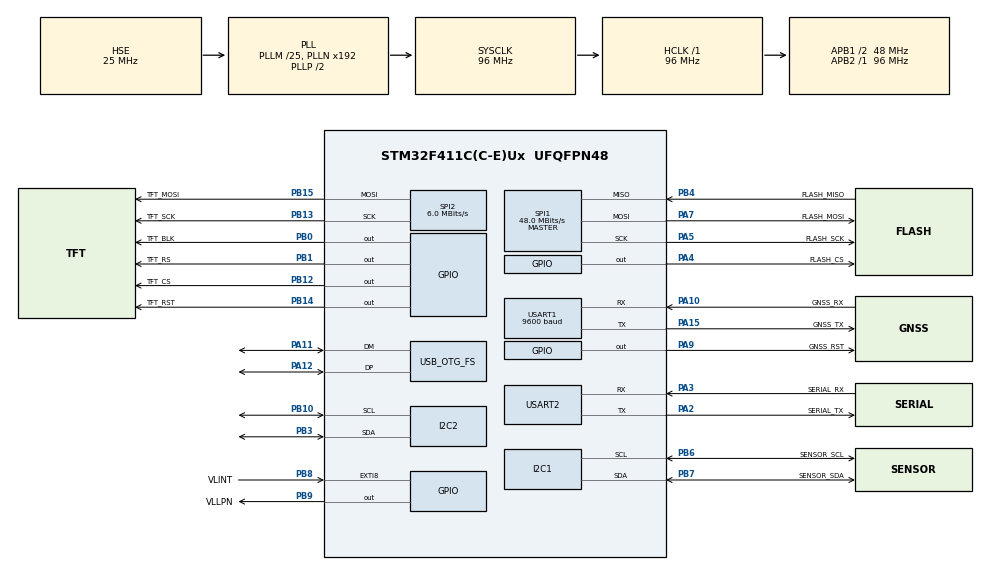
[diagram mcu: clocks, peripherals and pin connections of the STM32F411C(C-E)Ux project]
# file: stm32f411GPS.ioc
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Dma.I2C1_RX.5.Direction=DMA_PERIPH_TO_MEMORY
Dma.I2C1_RX.5.FIFOMode=DMA_FIFOMODE_DISABLE
Dma.I2C1_RX.5.Instance=DMA1_Stream0
Dma.I2C1_RX.5.MemDataAlignment=DMA_MDATAALIGN_BYTE
Dma.I2C1_RX.5.MemInc=DMA_MINC_ENABLE
Dma.I2C1_RX.5.Mode=DMA_NORMAL
Dma.I2C1_RX.5.PeriphDataAlignment=DMA_PDATAALIGN_BYTE
Dma.I2C1_RX.5.PeriphInc=DMA_PINC_DISABLE
Dma.I2C1_RX.5.Priority=DMA_PRIORITY_HIGH
Dma.I2C1_TX.8.Direction=DMA_MEMORY_TO_PERIPH
Dma.I2C1_TX.8.FIFOMode=DMA_FIFOMODE_DISABLE
Dma.I2C1_TX.8.Instance=DMA1_Stream1
Dma.I2C1_TX.8.MemDataAlignment=DMA_MDATAALIGN_BYTE
Dma.I2C1_TX.8.MemInc=DMA_MINC_ENABLE
Dma.I2C1_TX.8.Mode=DMA_NORMAL
Dma.I2C1_TX.8.PeriphDataAlignment=DMA_PDATAALIGN_BYTE
Dma.I2C1_TX.8.PeriphInc=DMA_PINC_DISABLE
Dma.I2C1_TX.8.Priority=DMA_PRIORITY_LOW
Dma.Request0=USART1_RX
Dma.Request1=USART1_TX
Dma.Request2=USART2_TX
Dma.Request3=USART2_RX
Dma.Request4=SPI1_TX
Dma.Request5=I2C1_RX
Dma.Request6=SPI1_RX
Dma.Request7=SPI2_TX
Dma.Request8=I2C1_TX
Dma.SPI1_RX.6.Direction=DMA_PERIPH_TO_MEMORY
Dma.SPI1_RX.6.FIFOMode=DMA_FIFOMODE_DISABLE
Dma.SPI1_RX.6.Instance=DMA2_Stream0
Dma.SPI1_RX.6.MemDataAlignment=DMA_MDATAALIGN_BYTE
Dma.SPI1_RX.6.MemInc=DMA_MINC_ENABLE
Dma.SPI1_RX.6.Mode=DMA_NORMAL
Dma.SPI1_RX.6.PeriphDataAlignment=DMA_PDATAALIGN_BYTE
Dma.SPI1_RX.6.PeriphInc=DMA_PINC_DISABLE
Dma.SPI1_RX.6.Priority=DMA_PRIORITY_LOW
Dma.SPI1_TX.4.Direction=DMA_MEMORY_TO_PERIPH
Dma.SPI1_TX.4.FIFOMode=DMA_FIFOMODE_DISABLE
Dma.SPI1_TX.4.Instance=DMA2_Stream3
Dma.SPI1_TX.4.MemDataAlignment=DMA_MDATAALIGN_BYTE
Dma.SPI1_TX.4.MemInc=DMA_MINC_ENABLE
Dma.SPI1_TX.4.Mode=DMA_NORMAL
Dma.SPI1_TX.4.PeriphDataAlignment=DMA_PDATAALIGN_BYTE
Dma.SPI1_TX.4.PeriphInc=DMA_PINC_DISABLE
Dma.SPI1_TX.4.Priority=DMA_PRIORITY_LOW
Dma.SPI2_TX.7.Direction=DMA_MEMORY_TO_PERIPH
Dma.SPI2_TX.7.FIFOMode=DMA_FIFOMODE_DISABLE
Dma.SPI2_TX.7.Instance=DMA1_Stream4
Dma.SPI2_TX.7.MemDataAlignment=DMA_MDATAALIGN_BYTE
Dma.SPI2_TX.7.MemInc=DMA_MINC_ENABLE
Dma.SPI2_TX.7.Mode=DMA_NORMAL
Dma.SPI2_TX.7.PeriphDataAlignment=DMA_PDATAALIGN_BYTE
Dma.SPI2_TX.7.PeriphInc=DMA_PINC_DISABLE
Dma.SPI2_TX.7.Priority=DMA_PRIORITY_LOW
Dma.USART1_RX.0.Direction=DMA_PERIPH_TO_MEMORY
Dma.USART1_RX.0.FIFOMode=DMA_FIFOMODE_DISABLE
Dma.USART1_RX.0.Instance=DMA2_Stream2
Dma.USART1_RX.0.MemDataAlignment=DMA_MDATAALIGN_BYTE
Dma.USART1_RX.0.MemInc=DMA_MINC_ENABLE
Dma.USART1_RX.0.Mode=DMA_NORMAL
Dma.USART1_RX.0.PeriphDataAlignment=DMA_PDATAALIGN_BYTE
Dma.USART1_RX.0.PeriphInc=DMA_PINC_DISABLE
Dma.USART1_RX.0.Priority=DMA_PRIORITY_LOW
Dma.USART1_TX.1.Direction=DMA_MEMORY_TO_PERIPH
Dma.USART1_TX.1.FIFOMode=DMA_FIFOMODE_DISABLE
Dma.USART1_TX.1.Instance=DMA2_Stream7
Dma.USART1_TX.1.MemDataAlignment=DMA_MDATAALIGN_BYTE
Dma.USART1_TX.1.MemInc=DMA_MINC_ENABLE
Dma.USART1_TX.1.Mode=DMA_NORMAL
Dma.USART1_TX.1.PeriphDataAlignment=DMA_PDATAALIGN_BYTE
Dma.USART1_TX.1.PeriphInc=DMA_PINC_DISABLE
Dma.USART1_TX.1.Priority=DMA_PRIORITY_LOW
Dma.USART2_RX.3.Direction=DMA_PERIPH_TO_MEMORY
Dma.USART2_RX.3.FIFOMode=DMA_FIFOMODE_DISABLE
Dma.USART2_RX.3.Instance=DMA1_Stream5
Dma.USART2_RX.3.MemDataAlignment=DMA_MDATAALIGN_BYTE
Dma.USART2_RX.3.MemInc=DMA_MINC_ENABLE
Dma.USART2_RX.3.Mode=DMA_NORMAL
Dma.USART2_RX.3.PeriphDataAlignment=DMA_PDATAALIGN_BYTE
Dma.USART2_RX.3.PeriphInc=DMA_PINC_DISABLE
Dma.USART2_RX.3.Priority=DMA_PRIORITY_LOW
Dma.USART2_TX.2.Direction=DMA_MEMORY_TO_PERIPH
Dma.USART2_TX.2.FIFOMode=DMA_FIFOMODE_DISABLE
Dma.USART2_TX.2.Instance=DMA1_Stream6
Dma.USART2_TX.2.MemDataAlignment=DMA_MDATAALIGN_BYTE
Dma.USART2_TX.2.MemInc=DMA_MINC_ENABLE
Dma.USART2_TX.2.Mode=DMA_NORMAL
Dma.USART2_TX.2.PeriphDataAlignment=DMA_PDATAALIGN_BYTE
Dma.USART2_TX.2.PeriphInc=DMA_PINC_DISABLE
Dma.USART2_TX.2.Priority=DMA_PRIORITY_LOW
FREERTOS.Tasks01=defaultTaskName,-3,128,defaultTask,Default,NULL,Dynamic,NULL,NULL
FREERTOS.configUSE_NEWLIB_REENTRANT=1
I2C1.I2C_Mode=I2C_Fast
Mcu.Family=STM32F4
Mcu.Name=STM32F411C(C-E)Ux
Mcu.Package=UFQFPN48
NVIC.DMA1_Stream0_IRQn=true\:12\:0\:true\:false\:true\:true\:false\:true\:true
NVIC.DMA1_Stream1_IRQn=true\:5\:0\:false\:false\:true\:true\:false\:true\:true
NVIC.DMA1_Stream4_IRQn=true\:5\:0\:false\:false\:true\:true\:false\:true\:true
NVIC.DMA1_Stream5_IRQn=true\:12\:0\:true\:false\:true\:true\:false\:true\:true
NVIC.DMA1_Stream6_IRQn=true\:12\:0\:true\:false\:true\:true\:false\:true\:true
NVIC.DMA2_Stream0_IRQn=true\:5\:0\:false\:false\:true\:true\:false\:true\:true
NVIC.DMA2_Stream2_IRQn=true\:12\:0\:true\:false\:true\:true\:false\:true\:true
NVIC.DMA2_Stream3_IRQn=true\:12\:0\:true\:false\:true\:true\:false\:true\:true
NVIC.DMA2_Stream7_IRQn=true\:12\:0\:true\:false\:true\:true\:false\:true\:true
NVIC.I2C1_ER_IRQn=true\:5\:0\:false\:false\:true\:true\:true\:true\:true
NVIC.I2C1_EV_IRQn=true\:5\:0\:false\:false\:true\:true\:true\:true\:true
NVIC.OTG_FS_IRQn=true\:5\:0\:false\:false\:true\:true\:false\:true\:true
NVIC.PriorityGroup=NVIC_PRIORITYGROUP_4
NVIC.SPI1_IRQn=true\:5\:0\:false\:false\:true\:true\:true\:true\:true
NVIC.SPI2_IRQn=true\:5\:0\:false\:false\:true\:true\:true\:true\:true
NVIC.TIM2_IRQn=true\:15\:0\:false\:false\:true\:false\:false\:true\:true
NVIC.TimeBase=TIM2_IRQn
NVIC.TimeBaseIP=TIM2
NVIC.USART1_IRQn=true\:12\:0\:true\:false\:true\:true\:true\:true\:true
NVIC.USART2_IRQn=true\:12\:0\:true\:false\:true\:true\:true\:true\:true
PA10.GPIO_Label=GNSS_RX
PA10.GPIO_PuPd=GPIO_PULLUP
PA10.Mode=Asynchronous
PA10.Signal=USART1_RX
PA11.Mode=Device_Only
PA11.Signal=USB_OTG_FS_DM
PA12.Mode=Device_Only
PA12.Signal=USB_OTG_FS_DP
PA13.Mode=Serial_Wire
PA13.Signal=SYS_JTMS-SWDIO
PA14.Mode=Serial_Wire
PA14.Signal=SYS_JTCK-SWCLK
PA15.GPIO_Label=GNSS_TX
PA15.GPIO_PuPd=GPIO_PULLUP
PA15.Mode=Asynchronous
PA15.Signal=USART1_TX
PA2.GPIO_Label=SERIAL_TX
PA2.Mode=Asynchronous
PA2.Signal=USART2_TX
PA3.GPIO_Label=SERIAL_RX
PA3.Mode=Asynchronous
PA3.Signal=USART2_RX
PA4.GPIO_Label=FLASH_CS
PA4.GPIO_PuPd=GPIO_PULLUP
PA4.Signal=GPIO_Output
PA5.GPIO_Label=FLASH_SCK
PA5.Mode=Full_Duplex_Master
PA5.Signal=SPI1_SCK
PA7.GPIO_Label=FLASH_MOSI
PA7.Mode=Full_Duplex_Master
PA7.Signal=SPI1_MOSI
PA9.GPIO_Label=GNSS_RST
PA9.GPIO_PuPd=GPIO_PULLUP
PA9.Signal=GPIO_Output
PB0.GPIO_Label=TFT_BLK
PB0.GPIO_PuPd=GPIO_PULLUP
PB0.Signal=GPIO_Output
PB1.GPIO_Label=TFT_RS
PB1.GPIO_PuPd=GPIO_PULLUP
PB1.Signal=GPIO_Output
PB10.Mode=I2C
PB10.Signal=I2C2_SCL
PB12.GPIO_Label=TFT_CS
PB12.GPIO_PuPd=GPIO_PULLUP
PB12.Signal=GPIO_Output
PB13.GPIO_Label=TFT_SCK
PB13.Mode=TX_Only_Simplex_Unidirect_Master
PB13.Signal=SPI2_SCK
PB14.GPIO_Label=TFT_RST
PB14.GPIO_PuPd=GPIO_PULLUP
PB14.Signal=GPIO_Output
PB15.GPIO_Label=TFT_MOSI
PB15.Mode=TX_Only_Simplex_Unidirect_Master
PB15.Signal=SPI2_MOSI
PB3.Mode=I2C
PB3.Signal=I2C2_SDA
PB4.GPIO_Label=FLASH_MISO
PB4.Mode=Full_Duplex_Master
PB4.Signal=SPI1_MISO
PB6.GPIO_Label=SENSOR_SCL
PB6.Mode=I2C
PB6.Signal=I2C1_SCL
PB7.GPIO_Label=SENSOR_SDA
PB7.Mode=I2C
PB7.Signal=I2C1_SDA
PB8.GPIO_Label=VLINT
PB8.Signal=GPXTI8
PB9.GPIO_Label=VLLPN
PB9.Signal=GPIO_Output
PC14-OSC32_IN.Mode=LSE-External-Oscillator
PC14-OSC32_IN.Signal=RCC_OSC32_IN
PC15-OSC32_OUT.Mode=LSE-External-Oscillator
PC15-OSC32_OUT.Signal=RCC_OSC32_OUT
PH0\ -\ OSC_IN.Mode=HSE-External-Oscillator
PH0\ -\ OSC_IN.Signal=RCC_OSC_IN
PH1\ -\ OSC_OUT.Mode=HSE-External-Oscillator
PH1\ -\ OSC_OUT.Signal=RCC_OSC_OUT
ProjectManager.HeapSize=0x200
ProjectManager.StackSize=0x400
ProjectManager.TargetToolchain=STM32CubeIDE
RCC.48MHZClocksFreq_Value=48000000
RCC.AHBFreq_Value=96000000
RCC.APB1CLKDivider=RCC_HCLK_DIV2
RCC.APB1Freq_Value=48000000
RCC.APB1TimFreq_Value=96000000
RCC.APB2Freq_Value=96000000
RCC.APB2TimFreq_Value=96000000
RCC.CortexFreq_Value=96000000
RCC.HCLKFreq_Value=96000000
RCC.HSE_VALUE=25000000
RCC.HSI_VALUE=16000000
RCC.PLLM=25
RCC.SYSCLKFreq_VALUE=96000000
RCC.SYSCLKSource=RCC_SYSCLKSOURCE_PLLCLK
RCC.VCOOutputFreq_Value=192000000
SPI1.BaudRatePrescaler=SPI_BAUDRATEPRESCALER_2
SPI1.CLKPolarity=SPI_POLARITY_LOW
SPI1.CalculateBaudRate=48.0 MBits/s
SPI1.Direction=SPI_DIRECTION_2LINES
SPI1.Mode=SPI_MODE_MASTER
SPI1.VirtualType=VM_MASTER
SPI2.BaudRatePrescaler=SPI_BAUDRATEPRESCALER_8
SPI2.CalculateBaudRate=6.0 MBits/s
SPI2.Direction=SPI_DIRECTION_2LINES
SPI2.Mode=SPI_MODE_MASTER
SPI2.VirtualType=VM_MASTER
TIM5.Prescaler=95
USART1.BaudRate=9600
USART1.VirtualMode=VM_ASYNC
USART2.VirtualMode=VM_ASYNC
USB_DEVICE.CLASS_NAME_FS=CDC
USB_DEVICE.VirtualMode=Cdc
USB_DEVICE.VirtualModeFS=Cdc_FS
USB_OTG_FS.VirtualMode=Device_Only
VP_FREERTOS_VS_CMSIS_V1.Mode=CMSIS_V1
VP_SYS_VS_tim2.Mode=TIM2
VP_TIM5_VS_ClockSourceINT.Mode=Internal
VP_USB_DEVICE_VS_USB_DEVICE_CDC_FS.Mode=CDC_FS
board=custom

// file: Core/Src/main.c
/* USER CODE BEGIN Header */
/**
  ******************************************************************************
  * @file           : main.c
  * @brief          : Main program body
  ******************************************************************************
  * @attention
  *
  * Copyright (c) 2023 STMicroelectronics.
  * All rights reserved.
  *
  * This software is licensed under terms that can be found in the LICENSE file
  * in the root directory of this software component.
  * If no LICENSE file comes with this software, it is provided AS-IS.
  *
  ******************************************************************************
  */
/* USER CODE END Header */
#include "main.h"
#include "cmsis_os.h"
#include "usb_device.h"

/* USER CODE BEGIN Includes */
#include "projectMain.h"
/* USER CODE END Includes */

osThreadId defaultTaskNameHandle;

void SystemClock_Config(void);
static void MX_GPIO_Init(void);
static void MX_DMA_Init(void);
static void MX_USART1_UART_Init(void);
static void MX_USART2_UART_Init(void);
static void MX_TIM5_Init(void);
static void MX_I2C1_Init(void);
static void MX_SPI1_Init(void);
static void MX_I2C2_Init(void);
static void MX_SPI2_Init(void);
void defaultTask(void const * argument);

/* USER CODE BEGIN PFP */
static void gnssTask(void *pvParameters);
static void lcdTask(void *pvParameters);
/* USER CODE END PFP */

int main(void)
{

  /* MCU Configuration--------------------------------------------------------*/

  /* Reset of all peripherals, Initializes the Flash interface and the Systick. */
  HAL_Init();

  /* Configure the system clock */
  SystemClock_Config();

  /* Initialize all configured peripherals */
  MX_GPIO_Init();
  MX_DMA_Init();
  MX_USART1_UART_Init();
  MX_USART2_UART_Init();
  MX_TIM5_Init();
  MX_I2C1_Init();
  MX_SPI1_Init();
  MX_I2C2_Init();
  MX_SPI2_Init();

  /* Create the thread(s) */
  /* definition and creation of defaultTaskName */
  osThreadDef(defaultTaskName, defaultTask, osPriorityIdle, 0, 128);
  defaultTaskNameHandle = osThreadCreate(osThread(defaultTaskName), NULL);

  /* USER CODE BEGIN RTOS_THREADS */
  /* add threads, ... */
  ProjectMain();
  /* USER CODE END RTOS_THREADS */

  /* Start scheduler */
  osKernelStart();
  /* We should never get here as control is now taken by the scheduler */
  /* Infinite loop */
  /* USER CODE BEGIN WHILE */
  while (1)
  {
    LL_mDelay(1000);
    /* USER CODE END WHILE */

  }
}

void SystemClock_Config(void)
{
  RCC_OscInitTypeDef RCC_OscInitStruct = {0};
  RCC_ClkInitTypeDef RCC_ClkInitStruct = {0};

  /** Configure the main internal regulator output voltage
  */
  __HAL_RCC_PWR_CLK_ENABLE();
  __HAL_PWR_VOLTAGESCALING_CONFIG(PWR_REGULATOR_VOLTAGE_SCALE1);

  /** Initializes the RCC Oscillators according to the specified parameters
  * in the RCC_OscInitTypeDef structure.
  */
  RCC_OscInitStruct.OscillatorType = RCC_OSCILLATORTYPE_HSE;
  RCC_OscInitStruct.HSEState = RCC_HSE_ON;
  RCC_OscInitStruct.PLL.PLLState = RCC_PLL_ON;
  RCC_OscInitStruct.PLL.PLLSource = RCC_PLLSOURCE_HSE;
  RCC_OscInitStruct.PLL.PLLM = 25;
  RCC_OscInitStruct.PLL.PLLN = 192;
  RCC_OscInitStruct.PLL.PLLP = RCC_PLLP_DIV2;
  RCC_OscInitStruct.PLL.PLLQ = 4;
  if (HAL_RCC_OscConfig(&RCC_OscInitStruct) != HAL_OK)
  {
    Error_Handler();
  }

  /** Initializes the CPU, AHB and APB buses clocks
  */
  RCC_ClkInitStruct.ClockType = RCC_CLOCKTYPE_HCLK|RCC_CLOCKTYPE_SYSCLK
                              |RCC_CLOCKTYPE_PCLK1|RCC_CLOCKTYPE_PCLK2;
  RCC_ClkInitStruct.SYSCLKSource = RCC_SYSCLKSOURCE_PLLCLK;
  RCC_ClkInitStruct.AHBCLKDivider = RCC_SYSCLK_DIV1;
  RCC_ClkInitStruct.APB1CLKDivider = RCC_HCLK_DIV2;
  RCC_ClkInitStruct.APB2CLKDivider = RCC_HCLK_DIV1;

  if (HAL_RCC_ClockConfig(&RCC_ClkInitStruct, FLASH_LATENCY_3) != HAL_OK)
  {
    Error_Handler();
  }
}

static void MX_I2C1_Init(void)
{

  LL_I2C_InitTypeDef I2C_InitStruct = {0};

  LL_GPIO_InitTypeDef GPIO_InitStruct = {0};

  LL_AHB1_GRP1_EnableClock(LL_AHB1_GRP1_PERIPH_GPIOB);
  /**I2C1 GPIO Configuration
  PB6   ------> I2C1_SCL
  PB7   ------> I2C1_SDA
  */
  GPIO_InitStruct.Pin = SENSOR_SCL_Pin|SENSOR_SDA_Pin;
  GPIO_InitStruct.Mode = LL_GPIO_MODE_ALTERNATE;
  GPIO_InitStruct.Speed = LL_GPIO_SPEED_FREQ_VERY_HIGH;
  GPIO_InitStruct.OutputType = LL_GPIO_OUTPUT_OPENDRAIN;
  GPIO_InitStruct.Pull = LL_GPIO_PULL_NO;
  GPIO_InitStruct.Alternate = LL_GPIO_AF_4;
  LL_GPIO_Init(GPIOB, &GPIO_InitStruct);

  /* Peripheral clock enable */
  LL_APB1_GRP1_EnableClock(LL_APB1_GRP1_PERIPH_I2C1);

  /* I2C1 DMA Init */

  /* I2C1_RX Init */
  LL_DMA_SetChannelSelection(DMA1, LL_DMA_STREAM_0, LL_DMA_CHANNEL_1);

  LL_DMA_SetDataTransferDirection(DMA1, LL_DMA_STREAM_0, LL_DMA_DIRECTION_PERIPH_TO_MEMORY);

  LL_DMA_SetStreamPriorityLevel(DMA1, LL_DMA_STREAM_0, LL_DMA_PRIORITY_HIGH);

  LL_DMA_SetMode(DMA1, LL_DMA_STREAM_0, LL_DMA_MODE_NORMAL);

  LL_DMA_SetPeriphIncMode(DMA1, LL_DMA_STREAM_0, LL_DMA_PERIPH_NOINCREMENT);

  LL_DMA_SetMemoryIncMode(DMA1, LL_DMA_STREAM_0, LL_DMA_MEMORY_INCREMENT);

  LL_DMA_SetPeriphSize(DMA1, LL_DMA_STREAM_0, LL_DMA_PDATAALIGN_BYTE);

  LL_DMA_SetMemorySize(DMA1, LL_DMA_STREAM_0, LL_DMA_MDATAALIGN_BYTE);

  LL_DMA_DisableFifoMode(DMA1, LL_DMA_STREAM_0);

  /* I2C1_TX Init */
  LL_DMA_SetChannelSelection(DMA1, LL_DMA_STREAM_1, LL_DMA_CHANNEL_0);

  LL_DMA_SetDataTransferDirection(DMA1, LL_DMA_STREAM_1, LL_DMA_DIRECTION_MEMORY_TO_PERIPH);

  LL_DMA_SetStreamPriorityLevel(DMA1, LL_DMA_STREAM_1, LL_DMA_PRIORITY_LOW);

  LL_DMA_SetMode(DMA1, LL_DMA_STREAM_1, LL_DMA_MODE_NORMAL);

  LL_DMA_SetPeriphIncMode(DMA1, LL_DMA_STREAM_1, LL_DMA_PERIPH_NOINCREMENT);

  LL_DMA_SetMemoryIncMode(DMA1, LL_DMA_STREAM_1, LL_DMA_MEMORY_INCREMENT);

  LL_DMA_SetPeriphSize(DMA1, LL_DMA_STREAM_1, LL_DMA_PDATAALIGN_BYTE);

  LL_DMA_SetMemorySize(DMA1, LL_DMA_STREAM_1, LL_DMA_MDATAALIGN_BYTE);

  LL_DMA_DisableFifoMode(DMA1, LL_DMA_STREAM_1);

  /* I2C1 interrupt Init */
  NVIC_SetPriority(I2C1_EV_IRQn, NVIC_EncodePriority(NVIC_GetPriorityGrouping(),5, 0));
  NVIC_EnableIRQ(I2C1_EV_IRQn);
  NVIC_SetPriority(I2C1_ER_IRQn, NVIC_EncodePriority(NVIC_GetPriorityGrouping(),5, 0));
  NVIC_EnableIRQ(I2C1_ER_IRQn);

  /** I2C Initialization
  */
  LL_I2C_DisableOwnAddress2(I2C1);
  LL_I2C_DisableGeneralCall(I2C1);
  LL_I2C_EnableClockStretching(I2C1);
  I2C_InitStruct.PeripheralMode = LL_I2C_MODE_I2C;
  I2C_InitStruct.ClockSpeed = 400000;
  I2C_InitStruct.DutyCycle = LL_I2C_DUTYCYCLE_2;
  I2C_InitStruct.OwnAddress1 = 0;
  I2C_InitStruct.TypeAcknowledge = LL_I2C_ACK;
  I2C_InitStruct.OwnAddrSize = LL_I2C_OWNADDRESS1_7BIT;
  LL_I2C_Init(I2C1, &I2C_InitStruct);
  LL_I2C_SetOwnAddress2(I2C1, 0);

}

static void MX_I2C2_Init(void)
{

  LL_I2C_InitTypeDef I2C_InitStruct = {0};

  LL_GPIO_InitTypeDef GPIO_InitStruct = {0};

  LL_AHB1_GRP1_EnableClock(LL_AHB1_GRP1_PERIPH_GPIOB);
  /**I2C2 GPIO Configuration
  PB10   ------> I2C2_SCL
  PB3   ------> I2C2_SDA
  */
  GPIO_InitStruct.Pin = LL_GPIO_PIN_10;
  GPIO_InitStruct.Mode = LL_GPIO_MODE_ALTERNATE;
  GPIO_InitStruct.Speed = LL_GPIO_SPEED_FREQ_VERY_HIGH;
  GPIO_InitStruct.OutputType = LL_GPIO_OUTPUT_OPENDRAIN;
  GPIO_InitStruct.Pull = LL_GPIO_PULL_NO;
  GPIO_InitStruct.Alternate = LL_GPIO_AF_4;
  LL_GPIO_Init(GPIOB, &GPIO_InitStruct);

  GPIO_InitStruct.Pin = LL_GPIO_PIN_3;
  GPIO_InitStruct.Mode = LL_GPIO_MODE_ALTERNATE;
  GPIO_InitStruct.Speed = LL_GPIO_SPEED_FREQ_VERY_HIGH;
  GPIO_InitStruct.OutputType = LL_GPIO_OUTPUT_OPENDRAIN;
  GPIO_InitStruct.Pull = LL_GPIO_PULL_NO;
  GPIO_InitStruct.Alternate = LL_GPIO_AF_9;
  LL_GPIO_Init(GPIOB, &GPIO_InitStruct);

  /* Peripheral clock enable */
  LL_APB1_GRP1_EnableClock(LL_APB1_GRP1_PERIPH_I2C2);

  /** I2C Initialization
  */
  LL_I2C_DisableOwnAddress2(I2C2);
  LL_I2C_DisableGeneralCall(I2C2);
  LL_I2C_EnableClockStretching(I2C2);
  I2C_InitStruct.PeripheralMode = LL_I2C_MODE_I2C;
  I2C_InitStruct.ClockSpeed = 100000;
  I2C_InitStruct.DutyCycle = LL_I2C_DUTYCYCLE_2;
  I2C_InitStruct.OwnAddress1 = 0;
  I2C_InitStruct.TypeAcknowledge = LL_I2C_ACK;
  I2C_InitStruct.OwnAddrSize = LL_I2C_OWNADDRESS1_7BIT;
  LL_I2C_Init(I2C2, &I2C_InitStruct);
  LL_I2C_SetOwnAddress2(I2C2, 0);

}

static void MX_SPI1_Init(void)
{

  LL_SPI_InitTypeDef SPI_InitStruct = {0};

  LL_GPIO_InitTypeDef GPIO_InitStruct = {0};

  /* Peripheral clock enable */
  LL_APB2_GRP1_EnableClock(LL_APB2_GRP1_PERIPH_SPI1);

  LL_AHB1_GRP1_EnableClock(LL_AHB1_GRP1_PERIPH_GPIOA);
  LL_AHB1_GRP1_EnableClock(LL_AHB1_GRP1_PERIPH_GPIOB);
  /**SPI1 GPIO Configuration
  PA5   ------> SPI1_SCK
  PA7   ------> SPI1_MOSI
  PB4   ------> SPI1_MISO
  */
  GPIO_InitStruct.Pin = FLASH_SCK_Pin|FLASH_MOSI_Pin;
  GPIO_InitStruct.Mode = LL_GPIO_MODE_ALTERNATE;
  GPIO_InitStruct.Speed = LL_GPIO_SPEED_FREQ_VERY_HIGH;
  GPIO_InitStruct.OutputType = LL_GPIO_OUTPUT_PUSHPULL;
  GPIO_InitStruct.Pull = LL_GPIO_PULL_NO;
  GPIO_InitStruct.Alternate = LL_GPIO_AF_5;
  LL_GPIO_Init(GPIOA, &GPIO_InitStruct);

  GPIO_InitStruct.Pin = FLASH_MISO_Pin;
  GPIO_InitStruct.Mode = LL_GPIO_MODE_ALTERNATE;
  GPIO_InitStruct.Speed = LL_GPIO_SPEED_FREQ_VERY_HIGH;
  GPIO_InitStruct.OutputType = LL_GPIO_OUTPUT_PUSHPULL;
  GPIO_InitStruct.Pull = LL_GPIO_PULL_NO;
  GPIO_InitStruct.Alternate = LL_GPIO_AF_5;
  LL_GPIO_Init(FLASH_MISO_GPIO_Port, &GPIO_InitStruct);

  /* SPI1 DMA Init */

  /* SPI1_TX Init */
  LL_DMA_SetChannelSelection(DMA2, LL_DMA_STREAM_3, LL_DMA_CHANNEL_3);

  LL_DMA_SetDataTransferDirection(DMA2, LL_DMA_STREAM_3, LL_DMA_DIRECTION_MEMORY_TO_PERIPH);

  LL_DMA_SetStreamPriorityLevel(DMA2, LL_DMA_STREAM_3, LL_DMA_PRIORITY_LOW);

  LL_DMA_SetMode(DMA2, LL_DMA_STREAM_3, LL_DMA_MODE_NORMAL);

  LL_DMA_SetPeriphIncMode(DMA2, LL_DMA_STREAM_3, LL_DMA_PERIPH_NOINCREMENT);

  LL_DMA_SetMemoryIncMode(DMA2, LL_DMA_STREAM_3, LL_DMA_MEMORY_INCREMENT);

  LL_DMA_SetPeriphSize(DMA2, LL_DMA_STREAM_3, LL_DMA_PDATAALIGN_BYTE);

  LL_DMA_SetMemorySize(DMA2, LL_DMA_STREAM_3, LL_DMA_MDATAALIGN_BYTE);

  LL_DMA_DisableFifoMode(DMA2, LL_DMA_STREAM_3);

  /* SPI1_RX Init */
  LL_DMA_SetChannelSelection(DMA2, LL_DMA_STREAM_0, LL_DMA_CHANNEL_3);

  LL_DMA_SetDataTransferDirection(DMA2, LL_DMA_STREAM_0, LL_DMA_DIRECTION_PERIPH_TO_MEMORY);

  LL_DMA_SetStreamPriorityLevel(DMA2, LL_DMA_STREAM_0, LL_DMA_PRIORITY_LOW);

  LL_DMA_SetMode(DMA2, LL_DMA_STREAM_0, LL_DMA_MODE_NORMAL);

  LL_DMA_SetPeriphIncMode(DMA2, LL_DMA_STREAM_0, LL_DMA_PERIPH_NOINCREMENT);

  LL_DMA_SetMemoryIncMode(DMA2, LL_DMA_STREAM_0, LL_DMA_MEMORY_INCREMENT);

  LL_DMA_SetPeriphSize(DMA2, LL_DMA_STREAM_0, LL_DMA_PDATAALIGN_BYTE);

  LL_DMA_SetMemorySize(DMA2, LL_DMA_STREAM_0, LL_DMA_MDATAALIGN_BYTE);

  LL_DMA_DisableFifoMode(DMA2, LL_DMA_STREAM_0);

  /* SPI1 interrupt Init */
  NVIC_SetPriority(SPI1_IRQn, NVIC_EncodePriority(NVIC_GetPriorityGrouping(),5, 0));
  NVIC_EnableIRQ(SPI1_IRQn);

  /* SPI1 parameter configuration*/
  SPI_InitStruct.TransferDirection = LL_SPI_FULL_DUPLEX;
  SPI_InitStruct.Mode = LL_SPI_MODE_MASTER;
  SPI_InitStruct.DataWidth = LL_SPI_DATAWIDTH_8BIT;
  SPI_InitStruct.ClockPolarity = LL_SPI_POLARITY_LOW;
  SPI_InitStruct.ClockPhase = LL_SPI_PHASE_1EDGE;
  SPI_InitStruct.NSS = LL_SPI_NSS_SOFT;
  SPI_InitStruct.BaudRate = LL_SPI_BAUDRATEPRESCALER_DIV2;
  SPI_InitStruct.BitOrder = LL_SPI_MSB_FIRST;
  SPI_InitStruct.CRCCalculation = LL_SPI_CRCCALCULATION_DISABLE;
  SPI_InitStruct.CRCPoly = 10;
  LL_SPI_Init(SPI1, &SPI_InitStruct);
  LL_SPI_SetStandard(SPI1, LL_SPI_PROTOCOL_MOTOROLA);

}

static void MX_SPI2_Init(void)
{

  LL_SPI_InitTypeDef SPI_InitStruct = {0};

  LL_GPIO_InitTypeDef GPIO_InitStruct = {0};

  /* Peripheral clock enable */
  LL_APB1_GRP1_EnableClock(LL_APB1_GRP1_PERIPH_SPI2);

  LL_AHB1_GRP1_EnableClock(LL_AHB1_GRP1_PERIPH_GPIOB);
  /**SPI2 GPIO Configuration
  PB13   ------> SPI2_SCK
  PB15   ------> SPI2_MOSI
  */
  GPIO_InitStruct.Pin = TFT_SCK_Pin|TFT_MOSI_Pin;
  GPIO_InitStruct.Mode = LL_GPIO_MODE_ALTERNATE;
  GPIO_InitStruct.Speed = LL_GPIO_SPEED_FREQ_VERY_HIGH;
  GPIO_InitStruct.OutputType = LL_GPIO_OUTPUT_PUSHPULL;
  GPIO_InitStruct.Pull = LL_GPIO_PULL_NO;
  GPIO_InitStruct.Alternate = LL_GPIO_AF_5;
  LL_GPIO_Init(GPIOB, &GPIO_InitStruct);

  /* SPI2 DMA Init */

  /* SPI2_TX Init */
  LL_DMA_SetChannelSelection(DMA1, LL_DMA_STREAM_4, LL_DMA_CHANNEL_0);

  LL_DMA_SetDataTransferDirection(DMA1, LL_DMA_STREAM_4, LL_DMA_DIRECTION_MEMORY_TO_PERIPH);

  LL_DMA_SetStreamPriorityLevel(DMA1, LL_DMA_STREAM_4, LL_DMA_PRIORITY_LOW);

  LL_DMA_SetMode(DMA1, LL_DMA_STREAM_4, LL_DMA_MODE_NORMAL);

  LL_DMA_SetPeriphIncMode(DMA1, LL_DMA_STREAM_4, LL_DMA_PERIPH_NOINCREMENT);

  LL_DMA_SetMemoryIncMode(DMA1, LL_DMA_STREAM_4, LL_DMA_MEMORY_INCREMENT);

  LL_DMA_SetPeriphSize(DMA1, LL_DMA_STREAM_4, LL_DMA_PDATAALIGN_BYTE);

  LL_DMA_SetMemorySize(DMA1, LL_DMA_STREAM_4, LL_DMA_MDATAALIGN_BYTE);

  LL_DMA_DisableFifoMode(DMA1, LL_DMA_STREAM_4);

  /* SPI2 interrupt Init */
  NVIC_SetPriority(SPI2_IRQn, NVIC_EncodePriority(NVIC_GetPriorityGrouping(),5, 0));
  NVIC_EnableIRQ(SPI2_IRQn);

  /* SPI2 parameter configuration*/
  SPI_InitStruct.TransferDirection = LL_SPI_FULL_DUPLEX;
  SPI_InitStruct.Mode = LL_SPI_MODE_MASTER;
  SPI_InitStruct.DataWidth = LL_SPI_DATAWIDTH_8BIT;
  SPI_InitStruct.ClockPolarity = LL_SPI_POLARITY_LOW;
  SPI_InitStruct.ClockPhase = LL_SPI_PHASE_1EDGE;
  SPI_InitStruct.NSS = LL_SPI_NSS_SOFT;
  SPI_InitStruct.BaudRate = LL_SPI_BAUDRATEPRESCALER_DIV8;
  SPI_InitStruct.BitOrder = LL_SPI_MSB_FIRST;
  SPI_InitStruct.CRCCalculation = LL_SPI_CRCCALCULATION_DISABLE;
  SPI_InitStruct.CRCPoly = 10;
  LL_SPI_Init(SPI2, &SPI_InitStruct);
  LL_SPI_SetStandard(SPI2, LL_SPI_PROTOCOL_MOTOROLA);

}

static void MX_TIM5_Init(void)
{

  LL_TIM_InitTypeDef TIM_InitStruct = {0};

  /* Peripheral clock enable */
  LL_APB1_GRP1_EnableClock(LL_APB1_GRP1_PERIPH_TIM5);

  TIM_InitStruct.Prescaler = 95;
  TIM_InitStruct.CounterMode = LL_TIM_COUNTERMODE_UP;
  TIM_InitStruct.Autoreload = 4294967295;
  TIM_InitStruct.ClockDivision = LL_TIM_CLOCKDIVISION_DIV1;
  LL_TIM_Init(TIM5, &TIM_InitStruct);
  LL_TIM_DisableARRPreload(TIM5);
  LL_TIM_SetClockSource(TIM5, LL_TIM_CLOCKSOURCE_INTERNAL);
  LL_TIM_SetTriggerOutput(TIM5, LL_TIM_TRGO_RESET);
  LL_TIM_DisableMasterSlaveMode(TIM5);

}

static void MX_USART1_UART_Init(void)
{

  LL_USART_InitTypeDef USART_InitStruct = {0};

  LL_GPIO_InitTypeDef GPIO_InitStruct = {0};

  /* Peripheral clock enable */
  LL_APB2_GRP1_EnableClock(LL_APB2_GRP1_PERIPH_USART1);

  LL_AHB1_GRP1_EnableClock(LL_AHB1_GRP1_PERIPH_GPIOA);
  /**USART1 GPIO Configuration
  PA10   ------> USART1_RX
  PA15   ------> USART1_TX
  */
  GPIO_InitStruct.Pin = GNSS_RX_Pin|GNSS_TX_Pin;
  GPIO_InitStruct.Mode = LL_GPIO_MODE_ALTERNATE;
  GPIO_InitStruct.Speed = LL_GPIO_SPEED_FREQ_VERY_HIGH;
  GPIO_InitStruct.OutputType = LL_GPIO_OUTPUT_PUSHPULL;
  GPIO_InitStruct.Pull = LL_GPIO_PULL_UP;
  GPIO_InitStruct.Alternate = LL_GPIO_AF_7;
  LL_GPIO_Init(GPIOA, &GPIO_InitStruct);

  /* USART1 DMA Init */

  /* USART1_RX Init */
  LL_DMA_SetChannelSelection(DMA2, LL_DMA_STREAM_2, LL_DMA_CHANNEL_4);

  LL_DMA_SetDataTransferDirection(DMA2, LL_DMA_STREAM_2, LL_DMA_DIRECTION_PERIPH_TO_MEMORY);

  LL_DMA_SetStreamPriorityLevel(DMA2, LL_DMA_STREAM_2, LL_DMA_PRIORITY_LOW);

  LL_DMA_SetMode(DMA2, LL_DMA_STREAM_2, LL_DMA_MODE_NORMAL);

  LL_DMA_SetPeriphIncMode(DMA2, LL_DMA_STREAM_2, LL_DMA_PERIPH_NOINCREMENT);

  LL_DMA_SetMemoryIncMode(DMA2, LL_DMA_STREAM_2, LL_DMA_MEMORY_INCREMENT);

  LL_DMA_SetPeriphSize(DMA2, LL_DMA_STREAM_2, LL_DMA_PDATAALIGN_BYTE);

  LL_DMA_SetMemorySize(DMA2, LL_DMA_STREAM_2, LL_DMA_MDATAALIGN_BYTE);

  LL_DMA_DisableFifoMode(DMA2, LL_DMA_STREAM_2);

  /* USART1_TX Init */
  LL_DMA_SetChannelSelection(DMA2, LL_DMA_STREAM_7, LL_DMA_CHANNEL_4);

  LL_DMA_SetDataTransferDirection(DMA2, LL_DMA_STREAM_7, LL_DMA_DIRECTION_MEMORY_TO_PERIPH);

  LL_DMA_SetStreamPriorityLevel(DMA2, LL_DMA_STREAM_7, LL_DMA_PRIORITY_LOW);

  LL_DMA_SetMode(DMA2, LL_DMA_STREAM_7, LL_DMA_MODE_NORMAL);

  LL_DMA_SetPeriphIncMode(DMA2, LL_DMA_STREAM_7, LL_DMA_PERIPH_NOINCREMENT);

  LL_DMA_SetMemoryIncMode(DMA2, LL_DMA_STREAM_7, LL_DMA_MEMORY_INCREMENT);

  LL_DMA_SetPeriphSize(DMA2, LL_DMA_STREAM_7, LL_DMA_PDATAALIGN_BYTE);

  LL_DMA_SetMemorySize(DMA2, LL_DMA_STREAM_7, LL_DMA_MDATAALIGN_BYTE);

  LL_DMA_DisableFifoMode(DMA2, LL_DMA_STREAM_7);

  /* USART1 interrupt Init */
  NVIC_SetPriority(USART1_IRQn, NVIC_EncodePriority(NVIC_GetPriorityGrouping(),12, 0));
  NVIC_EnableIRQ(USART1_IRQn);

  USART_InitStruct.BaudRate = 9600;
  USART_InitStruct.DataWidth = LL_USART_DATAWIDTH_8B;
  USART_InitStruct.StopBits = LL_USART_STOPBITS_1;
  USART_InitStruct.Parity = LL_USART_PARITY_NONE;
  USART_InitStruct.TransferDirection = LL_USART_DIRECTION_TX_RX;
  USART_InitStruct.HardwareFlowControl = LL_USART_HWCONTROL_NONE;
  USART_InitStruct.OverSampling = LL_USART_OVERSAMPLING_16;
  LL_USART_Init(USART1, &USART_InitStruct);
  LL_USART_ConfigAsyncMode(USART1);
  LL_USART_Enable(USART1);

}

static void MX_USART2_UART_Init(void)
{

  LL_USART_InitTypeDef USART_InitStruct = {0};

  LL_GPIO_InitTypeDef GPIO_InitStruct = {0};

  /* Peripheral clock enable */
  LL_APB1_GRP1_EnableClock(LL_APB1_GRP1_PERIPH_USART2);

  LL_AHB1_GRP1_EnableClock(LL_AHB1_GRP1_PERIPH_GPIOA);
  /**USART2 GPIO Configuration
  PA2   ------> USART2_TX
  PA3   ------> USART2_RX
  */
  GPIO_InitStruct.Pin = SERIAL_TX_Pin|SERIAL_RX_Pin;
  GPIO_InitStruct.Mode = LL_GPIO_MODE_ALTERNATE;
  GPIO_InitStruct.Speed = LL_GPIO_SPEED_FREQ_VERY_HIGH;
  GPIO_InitStruct.OutputType = LL_GPIO_OUTPUT_PUSHPULL;
  GPIO_InitStruct.Pull = LL_GPIO_PULL_NO;
  GPIO_InitStruct.Alternate = LL_GPIO_AF_7;
  LL_GPIO_Init(GPIOA, &GPIO_InitStruct);

  /* USART2 DMA Init */

  /* USART2_TX Init */
  LL_DMA_SetChannelSelection(DMA1, LL_DMA_STREAM_6, LL_DMA_CHANNEL_4);

  LL_DMA_SetDataTransferDirection(DMA1, LL_DMA_STREAM_6, LL_DMA_DIRECTION_MEMORY_TO_PERIPH);

  LL_DMA_SetStreamPriorityLevel(DMA1, LL_DMA_STREAM_6, LL_DMA_PRIORITY_LOW);

  LL_DMA_SetMode(DMA1, LL_DMA_STREAM_6, LL_DMA_MODE_NORMAL);

  LL_DMA_SetPeriphIncMode(DMA1, LL_DMA_STREAM_6, LL_DMA_PERIPH_NOINCREMENT);

  LL_DMA_SetMemoryIncMode(DMA1, LL_DMA_STREAM_6, LL_DMA_MEMORY_INCREMENT);

  LL_DMA_SetPeriphSize(DMA1, LL_DMA_STREAM_6, LL_DMA_PDATAALIGN_BYTE);

  LL_DMA_SetMemorySize(DMA1, LL_DMA_STREAM_6, LL_DMA_MDATAALIGN_BYTE);

  LL_DMA_DisableFifoMode(DMA1, LL_DMA_STREAM_6);

  /* USART2_RX Init */
  LL_DMA_SetChannelSelection(DMA1, LL_DMA_STREAM_5, LL_DMA_CHANNEL_4);

  LL_DMA_SetDataTransferDirection(DMA1, LL_DMA_STREAM_5, LL_DMA_DIRECTION_PERIPH_TO_MEMORY);

  LL_DMA_SetStreamPriorityLevel(DMA1, LL_DMA_STREAM_5, LL_DMA_PRIORITY_LOW);

  LL_DMA_SetMode(DMA1, LL_DMA_STREAM_5, LL_DMA_MODE_NORMAL);

  LL_DMA_SetPeriphIncMode(DMA1, LL_DMA_STREAM_5, LL_DMA_PERIPH_NOINCREMENT);

  LL_DMA_SetMemoryIncMode(DMA1, LL_DMA_STREAM_5, LL_DMA_MEMORY_INCREMENT);

  LL_DMA_SetPeriphSize(DMA1, LL_DMA_STREAM_5, LL_DMA_PDATAALIGN_BYTE);

  LL_DMA_SetMemorySize(DMA1, LL_DMA_STREAM_5, LL_DMA_MDATAALIGN_BYTE);

  LL_DMA_DisableFifoMode(DMA1, LL_DMA_STREAM_5);

  /* USART2 interrupt Init */
  NVIC_SetPriority(USART2_IRQn, NVIC_EncodePriority(NVIC_GetPriorityGrouping(),12, 0));
  NVIC_EnableIRQ(USART2_IRQn);

  USART_InitStruct.BaudRate = 115200;
  USART_InitStruct.DataWidth = LL_USART_DATAWIDTH_8B;
  USART_InitStruct.StopBits = LL_USART_STOPBITS_1;
  USART_InitStruct.Parity = LL_USART_PARITY_NONE;
  USART_InitStruct.TransferDirection = LL_USART_DIRECTION_TX_RX;
  USART_InitStruct.HardwareFlowControl = LL_USART_HWCONTROL_NONE;
  USART_InitStruct.OverSampling = LL_USART_OVERSAMPLING_16;
  LL_USART_Init(USART2, &USART_InitStruct);
  LL_USART_ConfigAsyncMode(USART2);
  LL_USART_Enable(USART2);

}

static void MX_DMA_Init(void)
{

  /* Init with LL driver */
  /* DMA controller clock enable */
  LL_AHB1_GRP1_EnableClock(LL_AHB1_GRP1_PERIPH_DMA2);
  LL_AHB1_GRP1_EnableClock(LL_AHB1_GRP1_PERIPH_DMA1);

  /* DMA interrupt init */
  /* DMA1_Stream0_IRQn interrupt configuration */
  NVIC_SetPriority(DMA1_Stream0_IRQn, NVIC_EncodePriority(NVIC_GetPriorityGrouping(),12, 0));
  NVIC_EnableIRQ(DMA1_Stream0_IRQn);
  /* DMA1_Stream1_IRQn interrupt configuration */
  NVIC_SetPriority(DMA1_Stream1_IRQn, NVIC_EncodePriority(NVIC_GetPriorityGrouping(),5, 0));
  NVIC_EnableIRQ(DMA1_Stream1_IRQn);
  /* DMA1_Stream4_IRQn interrupt configuration */
  NVIC_SetPriority(DMA1_Stream4_IRQn, NVIC_EncodePriority(NVIC_GetPriorityGrouping(),5, 0));
  NVIC_EnableIRQ(DMA1_Stream4_IRQn);
  /* DMA1_Stream5_IRQn interrupt configuration */
  NVIC_SetPriority(DMA1_Stream5_IRQn, NVIC_EncodePriority(NVIC_GetPriorityGrouping(),12, 0));
  NVIC_EnableIRQ(DMA1_Stream5_IRQn);
  /* DMA1_Stream6_IRQn interrupt configuration */
  NVIC_SetPriority(DMA1_Stream6_IRQn, NVIC_EncodePriority(NVIC_GetPriorityGrouping(),12, 0));
  NVIC_EnableIRQ(DMA1_Stream6_IRQn);
  /* DMA2_Stream0_IRQn interrupt configuration */
  NVIC_SetPriority(DMA2_Stream0_IRQn, NVIC_EncodePriority(NVIC_GetPriorityGrouping(),5, 0));
  NVIC_EnableIRQ(DMA2_Stream0_IRQn);
  /* DMA2_Stream2_IRQn interrupt configuration */
  NVIC_SetPriority(DMA2_Stream2_IRQn, NVIC_EncodePriority(NVIC_GetPriorityGrouping(),12, 0));
  NVIC_EnableIRQ(DMA2_Stream2_IRQn);
  /* DMA2_Stream3_IRQn interrupt configuration */
  NVIC_SetPriority(DMA2_Stream3_IRQn, NVIC_EncodePriority(NVIC_GetPriorityGrouping(),12, 0));
  NVIC_EnableIRQ(DMA2_Stream3_IRQn);
  /* DMA2_Stream7_IRQn interrupt configuration */
  NVIC_SetPriority(DMA2_Stream7_IRQn, NVIC_EncodePriority(NVIC_GetPriorityGrouping(),12, 0));
  NVIC_EnableIRQ(DMA2_Stream7_IRQn);

}

static void MX_GPIO_Init(void)
{
  LL_EXTI_InitTypeDef EXTI_InitStruct = {0};
  LL_GPIO_InitTypeDef GPIO_InitStruct = {0};

  /* GPIO Ports Clock Enable */
  LL_AHB1_GRP1_EnableClock(LL_AHB1_GRP1_PERIPH_GPIOC);
  LL_AHB1_GRP1_EnableClock(LL_AHB1_GRP1_PERIPH_GPIOH);
  LL_AHB1_GRP1_EnableClock(LL_AHB1_GRP1_PERIPH_GPIOA);
  LL_AHB1_GRP1_EnableClock(LL_AHB1_GRP1_PERIPH_GPIOB);

  /**/
  LL_GPIO_ResetOutputPin(GPIOA, FLASH_CS_Pin|GNSS_RST_Pin);

  /**/
  LL_GPIO_ResetOutputPin(GPIOB, TFT_BLK_Pin|TFT_RS_Pin|TFT_CS_Pin|TFT_RST_Pin
                          |VLLPN_Pin);

  /**/
  GPIO_InitStruct.Pin = FLASH_CS_Pin|GNSS_RST_Pin;
  GPIO_InitStruct.Mode = LL_GPIO_MODE_OUTPUT;
  GPIO_InitStruct.Speed = LL_GPIO_SPEED_FREQ_LOW;
  GPIO_InitStruct.OutputType = LL_GPIO_OUTPUT_PUSHPULL;
  GPIO_InitStruct.Pull = LL_GPIO_PULL_UP;
  LL_GPIO_Init(GPIOA, &GPIO_InitStruct);

  /**/
  GPIO_InitStruct.Pin = TFT_BLK_Pin|TFT_RS_Pin|TFT_CS_Pin|TFT_RST_Pin;
  GPIO_InitStruct.Mode = LL_GPIO_MODE_OUTPUT;
  GPIO_InitStruct.Speed = LL_GPIO_SPEED_FREQ_LOW;
  GPIO_InitStruct.OutputType = LL_GPIO_OUTPUT_PUSHPULL;
  GPIO_InitStruct.Pull = LL_GPIO_PULL_UP;
  LL_GPIO_Init(GPIOB, &GPIO_InitStruct);

  /**/
  GPIO_InitStruct.Pin = VLLPN_Pin;
  GPIO_InitStruct.Mode = LL_GPIO_MODE_OUTPUT;
  GPIO_InitStruct.Speed = LL_GPIO_SPEED_FREQ_LOW;
  GPIO_InitStruct.OutputType = LL_GPIO_OUTPUT_PUSHPULL;
  GPIO_InitStruct.Pull = LL_GPIO_PULL_NO;
  LL_GPIO_Init(VLLPN_GPIO_Port, &GPIO_InitStruct);

  /**/
  LL_SYSCFG_SetEXTISource(LL_SYSCFG_EXTI_PORTB, LL_SYSCFG_EXTI_LINE8);

  /**/
  EXTI_InitStruct.Line_0_31 = LL_EXTI_LINE_8;
  EXTI_InitStruct.LineCommand = ENABLE;
  EXTI_InitStruct.Mode = LL_EXTI_MODE_IT;
  EXTI_InitStruct.Trigger = LL_EXTI_TRIGGER_RISING;
  LL_EXTI_Init(&EXTI_InitStruct);

  /**/
  LL_GPIO_SetPinPull(VLINT_GPIO_Port, VLINT_Pin, LL_GPIO_PULL_NO);

  /**/
  LL_GPIO_SetPinMode(VLINT_GPIO_Port, VLINT_Pin, LL_GPIO_MODE_INPUT);

}

void defaultTask(void const * argument)
{
  /* init code for USB_DEVICE */
  MX_USB_DEVICE_Init();
  for(;;)
  {
    osDelay(1);
  }
}

void HAL_TIM_PeriodElapsedCallback(TIM_HandleTypeDef *htim)
{
  if (htim->Instance == TIM2) {
    HAL_IncTick();
  }
}

void Error_Handler(void)
{
  __disable_irq();
  while (1)
  {
  }
}
